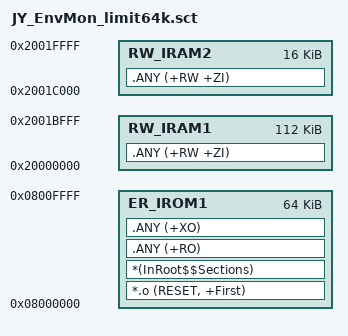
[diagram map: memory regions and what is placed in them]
; *****************************************************************************
; JY_EnvMon 固定分散加载文件（替代 Target 对话框自动生成的 .sct）
;
; 目的：程序镜像必须限制在 0x08000000-0x0800FFFF（64KB，Sector0~Sector3）。
;       Sector4(0x08010000) 起是元数据/数据缓存区（S4~S7），运行时会被擦写；
;       代码一旦越过 0x08010000，擦写 S4~S7 就会把自身代码擦掉，
;       表现为随机死机/不启动，且没有任何编译期提示。
;
; 为什么不用 Target 对话框：
;       Keil 打开工程时会按器件默认 Flash 大小回写 IROM1 Size，本项目已两次
;       被改回 0x80000（等于取消保护）。改用固定 scatter 文件后，
;       链接区域不再受 Target 对话框里 IROM1 Size 的影响。
;
; 核对方法：编译后看 map 文件
;   Load Region LR_IROM1 (Base: 0x08000000, ..., Max: 0x00010000, ABSOLUTE)
; 若 Max 不是 0x00010000，说明本文件没有被用上，立即停止烧录。
; *****************************************************************************

LR_IROM1 0x08000000 0x00010000  {          ; 代码/常量：仅 64KB
  ER_IROM1 0x08000000 0x00010000  {
   *.o (RESET, +First)
   *(InRoot$$Sections)
   .ANY (+RO)
   .ANY (+XO)
  }
  RW_IRAM1 0x20000000 0x0001C000  {        ; SRAM1 112KB
   .ANY (+RW +ZI)
  }
  RW_IRAM2 0x2001C000 0x00004000  {        ; SRAM2 16KB（当前未使用）
   .ANY (+RW +ZI)
  }
}
